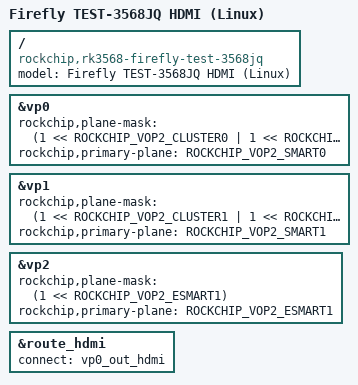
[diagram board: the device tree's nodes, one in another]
// SPDX-License-Identifier: (GPL-2.0+ OR MIT)
/*
 * Copyright (c) 2020 Rockchip Electronics Co., Ltd.
 *
 */

/dts-v1/;

#include <dt-bindings/display/rockchip_vop.h>
#include "rk3568-firefly-test-3568jq.dtsi"

/ {
    model = "Firefly TEST-3568JQ HDMI (Linux)";
    compatible = "rockchip,rk3568-firefly-test-3568jq", "rockchip,rk3568";
};

&vp0 {
	rockchip,plane-mask = <(1 << ROCKCHIP_VOP2_CLUSTER0 | 1 << ROCKCHIP_VOP2_ESMART0 | 1 << ROCKCHIP_VOP2_SMART0)>;
	rockchip,primary-plane = <ROCKCHIP_VOP2_SMART0>;
};

&vp1 {
	rockchip,plane-mask = <(1 << ROCKCHIP_VOP2_CLUSTER1 | 1 << ROCKCHIP_VOP2_SMART1)>;
	rockchip,primary-plane = <ROCKCHIP_VOP2_SMART1>;
};

&vp2 {
	rockchip,plane-mask = <(1 << ROCKCHIP_VOP2_ESMART1)>;
	rockchip,primary-plane = <ROCKCHIP_VOP2_ESMART1>;
};

&route_hdmi {
    status = "okay";
    connect = <&vp0_out_hdmi>;
};

